VERSION ""

NS_ :

BS_:

BU_:

BO_ 1536 EtasSteeringAngle129: 2 Vector__XXX
 SG_ EtasSteeringAngle129 : 0|16@1- (1,0) [0|0] "degrees" Vector__XXX

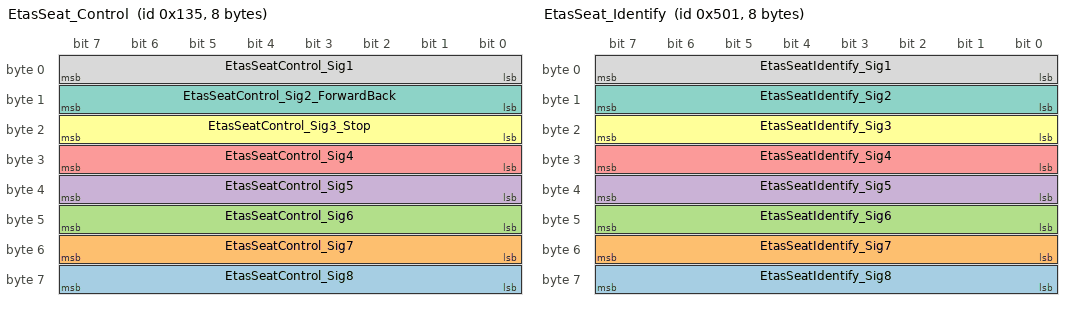
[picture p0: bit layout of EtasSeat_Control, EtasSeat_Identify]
BO_ 309 EtasSeat_Control: 8 Vector__XXX
 SG_ EtasSeatControl_Sig8 : 56|8@1+ (1,0) [0|0] "" Vector__XXX
 SG_ EtasSeatControl_Sig7 : 48|8@1+ (1,0) [0|0] "" Vector__XXX
 SG_ EtasSeatControl_Sig6 : 40|8@1+ (1,0) [0|0] "" Vector__XXX
 SG_ EtasSeatControl_Sig5 : 32|8@1+ (1,0) [0|0] "" Vector__XXX
 SG_ EtasSeatControl_Sig4 : 24|8@1+ (1,0) [0|0] "" Vector__XXX
 SG_ EtasSeatControl_Sig3_Stop : 16|8@1+ (1,0) [0|0] "" Vector__XXX
 SG_ EtasSeatControl_Sig2_ForwardBack : 8|8@1+ (1,0) [0|0] "" Vector__XXX
 SG_ EtasSeatControl_Sig1 : 0|8@1+ (1,0) [0|0] "" Vector__XXX

BO_ 1281 EtasSeat_Identify: 8 Vector__XXX
 SG_ EtasSeatIdentify_Sig8 : 56|8@1+ (1,0) [0|0] "" Vector__XXX
 SG_ EtasSeatIdentify_Sig7 : 48|8@1+ (1,0) [0|0] "" Vector__XXX
 SG_ EtasSeatIdentify_Sig6 : 40|8@1+ (1,0) [0|0] "" Vector__XXX
 SG_ EtasSeatIdentify_Sig5 : 32|8@1+ (1,0) [0|0] "" Vector__XXX
 SG_ EtasSeatIdentify_Sig4 : 24|8@1+ (1,0) [0|0] "" Vector__XXX
 SG_ EtasSeatIdentify_Sig3 : 16|8@1+ (1,0) [0|0] "" Vector__XXX
 SG_ EtasSeatIdentify_Sig2 : 8|8@1+ (1,0) [0|0] "" Vector__XXX
 SG_ EtasSeatIdentify_Sig1 : 0|8@1+ (1,0) [0|0] "" Vector__XXX

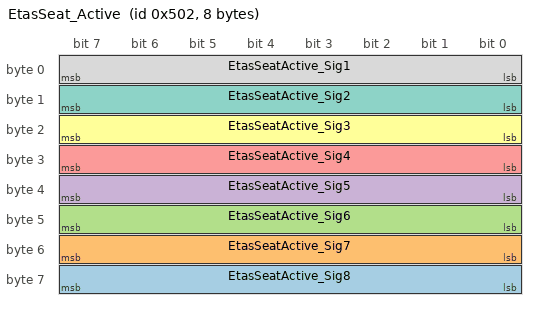
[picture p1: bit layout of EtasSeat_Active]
BO_ 1282 EtasSeat_Active: 8 Vector__XXX
 SG_ EtasSeatActive_Sig8 : 56|8@1+ (1,0) [0|0] "" Vector__XXX
 SG_ EtasSeatActive_Sig7 : 48|8@1+ (1,0) [0|0] "" Vector__XXX
 SG_ EtasSeatActive_Sig6 : 40|8@1+ (1,0) [0|0] "" Vector__XXX
 SG_ EtasSeatActive_Sig5 : 32|8@1+ (1,0) [0|0] "" Vector__XXX
 SG_ EtasSeatActive_Sig4 : 24|8@1+ (1,0) [0|0] "" Vector__XXX
 SG_ EtasSeatActive_Sig3 : 16|8@1+ (1,0) [0|0] "" Vector__XXX
 SG_ EtasSeatActive_Sig2 : 8|8@1+ (1,0) [0|0] "" Vector__XXX
 SG_ EtasSeatActive_Sig1 : 0|8@1+ (1,0) [0|0] "" Vector__XXX

BO_ 599 EtasVehicleSpeed: 4 Vector__XXX
 SG_ EtasVehicleSpeed : 0|32@1- (0.08,-40) [-40|285] "km/h" Vector__XXX

EV_ EnvKlemme30: 0 [0|1] "" 1 1 DUMMY_NODE_VECTOR0 Vector__XXX;

EV_ EnvKlemme15: 0 [0|1] "" 0 2 DUMMY_NODE_VECTOR0 Vector__XXX;

BA_DEF_ BU_  "NodeLayerModules" STRING ;
BA_DEF_ BO_  "GenMsgILSupport" ENUM  "No","Yes";
BA_DEF_  "NmBaseAddress" HEX 1024 1087;
BA_DEF_ BO_  "GenMsgSendType" ENUM  "Cyclic","NotUsed","NotUsed","NotUsed","NotUsed","NotUsed","NotUsed","IfActive","NoMsgSendType","NotUsed","vector_leerstring";
BA_DEF_ SG_  "GenSigSendType" ENUM  "Cyclic","OnWrite","OnWriteWithRepetition","OnChange","OnChangeWithRepetition","IfActive","IfActiveWithRepetition","NoSigSendType","NotUsed","NotUsed","NotUsed","NotUsed","NotUsed";
BA_DEF_ SG_  "GenSigStartValue" FLOAT 0 100000000000;
BA_DEF_DEF_  "NodeLayerModules" "CANoeILNLVector.dll";
BA_DEF_DEF_  "GenMsgILSupport" "Yes";
BA_DEF_DEF_  "NmBaseAddress" 1024;
BA_DEF_DEF_  "GenMsgSendType" "NoMsgSendType";
BA_DEF_DEF_  "GenSigSendType" "Cyclic";
BA_DEF_DEF_  "GenSigStartValue" 0;
BA_ "GenSigStartValue" SG_ 599 EtasVehicleSpeed 500;
SIG_VALTYPE_ 599 EtasVehicleSpeed : 1;
